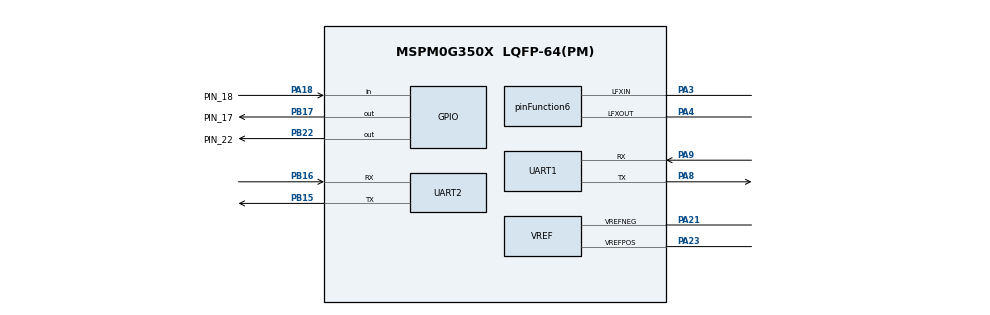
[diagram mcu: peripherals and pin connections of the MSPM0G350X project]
/**
 * @cliArgs --device "MSPM0G350X" --part "Default" --package "LQFP-64(PM)" --product "mspm0_sdk@2.04.00.06"
 * @versions {"tool":"1.23.1+4034"}
 */

/**
 * Import the modules used in this configuration.
 */
const GPIO    = scripting.addModule("/ti/driverlib/GPIO", {}, false);
const GPIO1   = GPIO.addInstance();
const GPIO2   = GPIO.addInstance();
const GPIO3   = GPIO.addInstance();
const UART    = scripting.addModule("/ti/driverlib/UART", {}, false);
const UART1   = UART.addInstance();
const UART2   = UART.addInstance();
const SYSCTL  = scripting.addModule("/ti/driverlib/SYSCTL");
const SYSTICK = scripting.addModule("/ti/driverlib/SYSTICK");
const VREF    = scripting.addModule("/ti/driverlib/VREF");

/**
 * Write custom configuration values to the imported modules.
 */
const divider2       = system.clockTree["HFCLK4MFPCLKDIV"];
divider2.divideValue = 10;

const divider9       = system.clockTree["UDIV"];
divider9.divideValue = 2;

const gate7  = system.clockTree["MFCLKGATE"];
gate7.enable = true;

const gate8  = system.clockTree["MFPCLKGATE"];
gate8.enable = true;

const multiplier2         = system.clockTree["PLL_QDIV"];
multiplier2.multiplyValue = 4;

const mux4       = system.clockTree["EXHFMUX"];
mux4.inputSelect = "EXHFMUX_XTAL";

const mux5       = system.clockTree["EXLFMUX"];
mux5.inputSelect = "EXLFMUX_XTAL";

const mux8       = system.clockTree["HSCLKMUX"];
mux8.inputSelect = "HSCLKMUX_SYSPLL0";

const mux9       = system.clockTree["LFXTMUX"];
mux9.inputSelect = "LFXTMUX_TRUE";

const mux12       = system.clockTree["SYSPLLMUX"];
mux12.inputSelect = "zSYSPLLMUX_HFCLK";

const pinFunction4     = system.clockTree["HFXT"];
pinFunction4.inputFreq = 40;
pinFunction4.enable    = true;

const pinFunction6                        = system.clockTree["LFXT"];
pinFunction6.inputFreq                    = 32.768;
pinFunction6.enable                       = true;
pinFunction6.peripheral.$assign           = "SYSCTL";
pinFunction6.peripheral.lfxInPin.$assign  = "PA3";
pinFunction6.peripheral.lfxOutPin.$assign = "PA4";

GPIO1.port                               = "PORTB";
GPIO1.$name                              = "LED_PB22";
GPIO1.associatedPins[0].internalResistor = "PULL_DOWN";
GPIO1.associatedPins[0].$name            = "PIN_22";
GPIO1.associatedPins[0].assignedPin      = "22";
GPIO1.associatedPins[0].pin.$assign      = "PB22";

const Board = scripting.addModule("/ti/driverlib/Board", {}, false);

GPIO2.port                               = "PORTA";
GPIO2.$name                              = "KEY_BSL";
GPIO2.associatedPins[0].$name            = "PIN_18";
GPIO2.associatedPins[0].direction        = "INPUT";
GPIO2.associatedPins[0].assignedPin      = "18";
GPIO2.associatedPins[0].internalResistor = "PULL_DOWN";
GPIO2.associatedPins[0].interruptEn      = true;
GPIO2.associatedPins[0].polarity         = "RISE";
GPIO2.associatedPins[0].pin.$assign      = "PA18";

GPIO3.port                               = "PORTB";
GPIO3.$name                              = "RS485_DE";
GPIO3.associatedPins[0].$name            = "PIN_17";
GPIO3.associatedPins[0].direction        = "OUTPUT";
GPIO3.associatedPins[0].initialValue     = "CLEARED";
GPIO3.associatedPins[0].assignedPin      = "17";
GPIO3.associatedPins[0].pin.$assign      = "PB17";

UART1.$name                    = "UART_MAIXCAM";
UART1.rxFifoThreshold          = "DL_UART_RX_FIFO_LEVEL_ONE_ENTRY";
UART1.enableDMARX              = false;
UART1.enableDMATX              = false;
UART1.targetBaudRate           = 115200;
UART1.peripheral.$assign       = "UART1";
UART1.peripheral.rxPin.$assign = "PA9";
UART1.peripheral.txPin.$assign = "PA8";
UART1.txPinConfig.$name        = "ti_driverlib_gpio_GPIOPinGeneric31";
UART1.rxPinConfig.$name        = "ti_driverlib_gpio_GPIOPinGeneric32";

UART2.$name                    = "UART_X42S";
UART2.rxFifoThreshold          = "DL_UART_RX_FIFO_LEVEL_ONE_ENTRY";
UART2.enableDMARX              = false;
UART2.enableDMATX              = false;
UART2.targetBaudRate           = 115200;
UART2.peripheral.$assign       = "UART2";
UART2.peripheral.rxPin.$assign = "PB16";
UART2.peripheral.txPin.$assign = "PB15";
UART2.txPinConfig.$name        = "ti_driverlib_gpio_GPIOPinGeneric33";
UART2.rxPinConfig.$name        = "ti_driverlib_gpio_GPIOPinGeneric34";

SYSCTL.forceDefaultClkConfig = true;
SYSCTL.clockTreeEn           = true;
scripting.suppress("For best practices when the CPUCLK is running at 32MHz and above, clear the flash status bit using DL_FlashCTL_executeClearStatus\\(\\) before executing any flash operation\\. Otherwise there may be false positives\\.", SYSCTL);

SYSTICK.periodEnable      = true;
SYSTICK.interruptPriority = "0";
SYSTICK.systickEnable     = true;
SYSTICK.period            = 80;

VREF.basicVrefPins                 = "VREF+-";
VREF.basicIntVolt                  = "DL_VREF_BUFCONFIG_OUTPUT_2_5V";
VREF.basicMode                     = "DL_VREF_ENABLE_DISABLE";
VREF.basicExtVolt                  = 3.3;
VREF.vrefPosPinConfig.$name        = "ti_driverlib_gpio_GPIOPinGeneric29";
VREF.peripheral.$assign            = "VREF";
VREF.peripheral.vrefPosPin.$assign = "PA23";
VREF.peripheral.vrefNegPin.$assign = "PA21";
VREF.vrefNegPinConfig.$name        = "ti_driverlib_gpio_GPIOPinGeneric30";

/**
 * Pinmux solution for unlocked pins/peripherals. This ensures that minor changes to the automatic solver in a future
 * version of the tool will not impact the pinmux you originally saw.  These lines can be completely deleted in order to
 * re-solve from scratch.
 */
pinFunction4.peripheral.$suggestSolution           = "SYSCTL";
pinFunction4.peripheral.hfxInPin.$suggestSolution  = "PA5";
pinFunction4.peripheral.hfxOutPin.$suggestSolution = "PA6";
Board.peripheral.$suggestSolution                  = "DEBUGSS";
Board.peripheral.swclkPin.$suggestSolution         = "PA20";
Board.peripheral.swdioPin.$suggestSolution         = "PA19";
